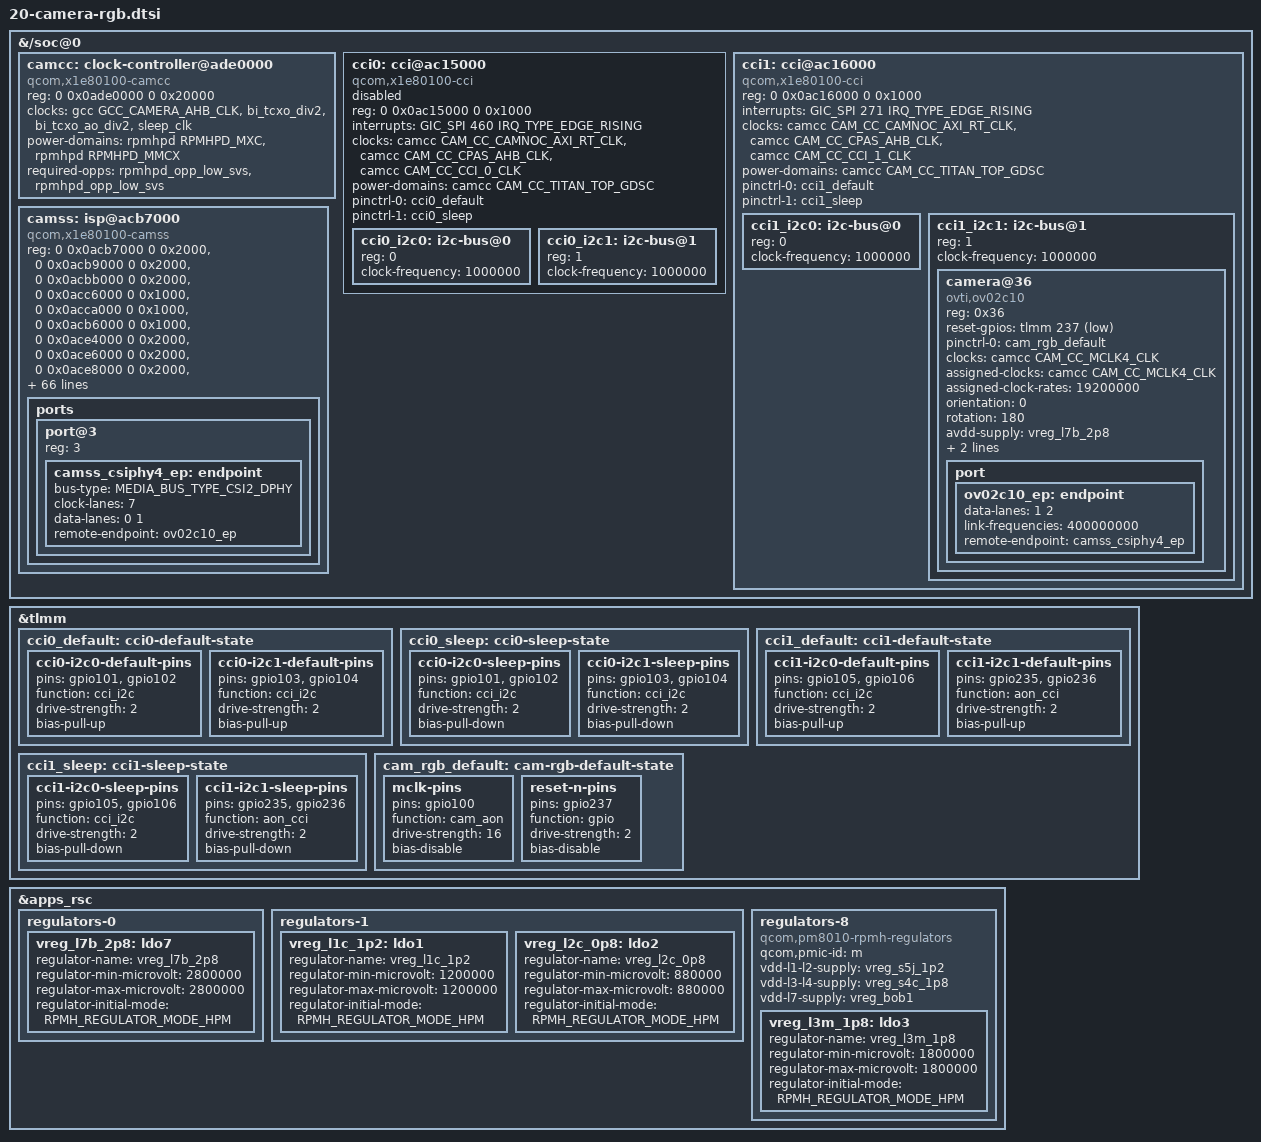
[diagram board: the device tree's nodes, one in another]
// SPDX-License-Identifier: BSD-3-Clause
/*
 * Front RGB camera of the ASUS Vivobook S 15 (S5507QAD), overlay fragment.
 *
 * Part 1 (SoC): camcc, CCI0/CCI1, CAMSS (x1e80100 / hamoa).
 * Part 2 (board): supplies, pins and the OV02C10 sensor.
 *
 * Fedora kernels 7.2 and 7.3 have the drivers (camcc-x1e80100, i2c-qcom-cci,
 * qcom-camss with x1e80100 data), but hamoa.dtsi has none of these nodes,
 * so the overlay adds them completely instead of just enabling them.
 *
 * Origin of the values:
 *  - camcc, cci0, cci1, CCI pins: hamoa.dtsi of the Ubuntu linux-qcom-x1e
 *    7.3.0-21.21 kernel (Bryan O'Donoghue's "x1e80100: Add CAMCC/CCI"
 *    series), identical to HurlyDesousa/linux-aarch64-vivobook patch 0003.
 *  - camss: the "legacy" binding with the CSIPHYs inside CAMSS
 *    (Documentation/devicetree/bindings/media/qcom,x1e80100-camss.yaml of
 *    7.2; no phys/simple-mfd/separate csiphy nodes, that is the newer PHY
 *    API series). Taken from Ubuntu 7.3, which worked on this laptop: the
 *    vfe0/vfe1 register size 0xf000 and the iommus list.
 *  - CSIPHY supplies belong to the board, see part 2.
 *
 * The IR camera fragment (30-camera-ir.dtsi) reuses these nodes: it enables
 * &cci0 and adds its own port@N to &camss.
 */

#include <dt-bindings/clock/qcom,x1e80100-camcc.h>
#include <dt-bindings/clock/qcom,x1e80100-gcc.h>
#include <dt-bindings/gpio/gpio.h>
#include <dt-bindings/interconnect/qcom,icc.h>
#include <dt-bindings/interconnect/qcom,x1e80100-rpmh.h>
#include <dt-bindings/interrupt-controller/arm-gic.h>
#include <dt-bindings/media/video-interfaces.h>
#include <dt-bindings/power/qcom,rpmhpd.h>
#include <dt-bindings/regulator/qcom,rpmh-regulator.h>

/* ======================= SoC part ======================= */

&{/soc@0} {
	camcc: clock-controller@ade0000 {
		compatible = "qcom,x1e80100-camcc";
		reg = <0 0x0ade0000 0 0x20000>;
		clocks = <&gcc GCC_CAMERA_AHB_CLK>,
			 <&bi_tcxo_div2>,
			 <&bi_tcxo_ao_div2>,
			 <&sleep_clk>;
		power-domains = <&rpmhpd RPMHPD_MXC>,
				<&rpmhpd RPMHPD_MMCX>;
		required-opps = <&rpmhpd_opp_low_svs>,
				<&rpmhpd_opp_low_svs>;
		#clock-cells = <1>;
		#reset-cells = <1>;
		#power-domain-cells = <1>;
	};

	cci0: cci@ac15000 {
		compatible = "qcom,x1e80100-cci", "qcom,msm8996-cci";
		reg = <0 0x0ac15000 0 0x1000>;

		interrupts = <GIC_SPI 460 IRQ_TYPE_EDGE_RISING>;

		clocks = <&camcc CAM_CC_CAMNOC_AXI_RT_CLK>,
			 <&camcc CAM_CC_CPAS_AHB_CLK>,
			 <&camcc CAM_CC_CCI_0_CLK>;
		clock-names = "camnoc_axi",
			      "cpas_ahb",
			      "cci";

		power-domains = <&camcc CAM_CC_TITAN_TOP_GDSC>;

		pinctrl-0 = <&cci0_default>;
		pinctrl-1 = <&cci0_sleep>;
		pinctrl-names = "default", "sleep";

		#address-cells = <1>;
		#size-cells = <0>;

		status = "disabled";

		cci0_i2c0: i2c-bus@0 {
			reg = <0>;
			clock-frequency = <1000000>;
			#address-cells = <1>;
			#size-cells = <0>;
		};

		cci0_i2c1: i2c-bus@1 {
			reg = <1>;
			clock-frequency = <1000000>;
			#address-cells = <1>;
			#size-cells = <0>;
		};
	};

	cci1: cci@ac16000 {
		compatible = "qcom,x1e80100-cci", "qcom,msm8996-cci";
		reg = <0 0x0ac16000 0 0x1000>;

		interrupts = <GIC_SPI 271 IRQ_TYPE_EDGE_RISING>;

		clocks = <&camcc CAM_CC_CAMNOC_AXI_RT_CLK>,
			 <&camcc CAM_CC_CPAS_AHB_CLK>,
			 <&camcc CAM_CC_CCI_1_CLK>;
		clock-names = "camnoc_axi",
			      "cpas_ahb",
			      "cci";

		power-domains = <&camcc CAM_CC_TITAN_TOP_GDSC>;

		pinctrl-0 = <&cci1_default>;
		pinctrl-1 = <&cci1_sleep>;
		pinctrl-names = "default", "sleep";

		#address-cells = <1>;
		#size-cells = <0>;

		status = "disabled";

		cci1_i2c0: i2c-bus@0 {
			reg = <0>;
			clock-frequency = <1000000>;
			#address-cells = <1>;
			#size-cells = <0>;
		};

		cci1_i2c1: i2c-bus@1 {
			reg = <1>;
			clock-frequency = <1000000>;
			#address-cells = <1>;
			#size-cells = <0>;
		};
	};

	camss: isp@acb7000 {
		compatible = "qcom,x1e80100-camss";

		reg = <0 0x0acb7000 0 0x2000>,
		      <0 0x0acb9000 0 0x2000>,
		      <0 0x0acbb000 0 0x2000>,
		      <0 0x0acc6000 0 0x1000>,
		      <0 0x0acca000 0 0x1000>,
		      <0 0x0acb6000 0 0x1000>,
		      <0 0x0ace4000 0 0x2000>,
		      <0 0x0ace6000 0 0x2000>,
		      <0 0x0ace8000 0 0x2000>,
		      <0 0x0acec000 0 0x4000>,
		      <0 0x0acf6000 0 0x1000>,
		      <0 0x0acf7000 0 0x1000>,
		      <0 0x0acf8000 0 0x1000>,
		      <0 0x0ac62000 0 0xf000>,
		      <0 0x0ac71000 0 0xf000>,
		      <0 0x0acc7000 0 0x2000>,
		      <0 0x0accb000 0 0x2000>;
		reg-names = "csid0", "csid1", "csid2",
			    "csid_lite0", "csid_lite1",
			    "csid_wrapper",
			    "csiphy0", "csiphy1", "csiphy2", "csiphy4",
			    "csitpg0", "csitpg1", "csitpg2",
			    "vfe0", "vfe1",
			    "vfe_lite0", "vfe_lite1";

		clocks = <&camcc CAM_CC_CAMNOC_AXI_NRT_CLK>,
			 <&camcc CAM_CC_CAMNOC_AXI_RT_CLK>,
			 <&camcc CAM_CC_CORE_AHB_CLK>,
			 <&camcc CAM_CC_CPAS_AHB_CLK>,
			 <&camcc CAM_CC_CPAS_FAST_AHB_CLK>,
			 <&camcc CAM_CC_CPAS_IFE_0_CLK>,
			 <&camcc CAM_CC_CPAS_IFE_1_CLK>,
			 <&camcc CAM_CC_CPAS_IFE_LITE_CLK>,
			 <&camcc CAM_CC_CPHY_RX_CLK_SRC>,
			 <&camcc CAM_CC_CSID_CLK>,
			 <&camcc CAM_CC_CSID_CSIPHY_RX_CLK>,
			 <&camcc CAM_CC_CSIPHY0_CLK>,
			 <&camcc CAM_CC_CSI0PHYTIMER_CLK>,
			 <&camcc CAM_CC_CSIPHY1_CLK>,
			 <&camcc CAM_CC_CSI1PHYTIMER_CLK>,
			 <&camcc CAM_CC_CSIPHY2_CLK>,
			 <&camcc CAM_CC_CSI2PHYTIMER_CLK>,
			 <&camcc CAM_CC_CSIPHY4_CLK>,
			 <&camcc CAM_CC_CSI4PHYTIMER_CLK>,
			 <&gcc GCC_CAMERA_HF_AXI_CLK>,
			 <&gcc GCC_CAMERA_SF_AXI_CLK>,
			 <&camcc CAM_CC_IFE_0_CLK>,
			 <&camcc CAM_CC_IFE_0_FAST_AHB_CLK>,
			 <&camcc CAM_CC_IFE_1_CLK>,
			 <&camcc CAM_CC_IFE_1_FAST_AHB_CLK>,
			 <&camcc CAM_CC_IFE_LITE_CLK>,
			 <&camcc CAM_CC_IFE_LITE_AHB_CLK>,
			 <&camcc CAM_CC_IFE_LITE_CPHY_RX_CLK>,
			 <&camcc CAM_CC_IFE_LITE_CSID_CLK>;
		clock-names = "camnoc_nrt_axi", "camnoc_rt_axi",
			      "core_ahb", "cpas_ahb", "cpas_fast_ahb",
			      "cpas_vfe0", "cpas_vfe1", "cpas_vfe_lite",
			      "cphy_rx_clk_src", "csid", "csid_csiphy_rx",
			      "csiphy0", "csiphy0_timer",
			      "csiphy1", "csiphy1_timer",
			      "csiphy2", "csiphy2_timer",
			      "csiphy4", "csiphy4_timer",
			      "gcc_axi_hf", "gcc_axi_sf",
			      "vfe0", "vfe0_fast_ahb",
			      "vfe1", "vfe1_fast_ahb",
			      "vfe_lite", "vfe_lite_ahb",
			      "vfe_lite_cphy_rx", "vfe_lite_csid";

		interrupts = <GIC_SPI 464 IRQ_TYPE_EDGE_RISING>,
			     <GIC_SPI 466 IRQ_TYPE_EDGE_RISING>,
			     <GIC_SPI 431 IRQ_TYPE_EDGE_RISING>,
			     <GIC_SPI 468 IRQ_TYPE_EDGE_RISING>,
			     <GIC_SPI 359 IRQ_TYPE_EDGE_RISING>,
			     <GIC_SPI 477 IRQ_TYPE_EDGE_RISING>,
			     <GIC_SPI 478 IRQ_TYPE_EDGE_RISING>,
			     <GIC_SPI 479 IRQ_TYPE_EDGE_RISING>,
			     <GIC_SPI 122 IRQ_TYPE_EDGE_RISING>,
			     <GIC_SPI 465 IRQ_TYPE_EDGE_RISING>,
			     <GIC_SPI 467 IRQ_TYPE_EDGE_RISING>,
			     <GIC_SPI 469 IRQ_TYPE_EDGE_RISING>,
			     <GIC_SPI 360 IRQ_TYPE_EDGE_RISING>;
		interrupt-names = "csid0", "csid1", "csid2",
				  "csid_lite0", "csid_lite1",
				  "csiphy0", "csiphy1", "csiphy2", "csiphy4",
				  "vfe0", "vfe1",
				  "vfe_lite0", "vfe_lite1";

		interconnects = <&gem_noc MASTER_APPSS_PROC QCOM_ICC_TAG_ACTIVE_ONLY
				 &config_noc SLAVE_CAMERA_CFG QCOM_ICC_TAG_ACTIVE_ONLY>,
				<&mmss_noc MASTER_CAMNOC_HF QCOM_ICC_TAG_ALWAYS
				 &mc_virt SLAVE_EBI1 QCOM_ICC_TAG_ALWAYS>,
				<&mmss_noc MASTER_CAMNOC_SF QCOM_ICC_TAG_ALWAYS
				 &mc_virt SLAVE_EBI1 QCOM_ICC_TAG_ALWAYS>,
				<&mmss_noc MASTER_CAMNOC_ICP QCOM_ICC_TAG_ALWAYS
				 &mc_virt SLAVE_EBI1 QCOM_ICC_TAG_ALWAYS>;
		interconnect-names = "ahb", "hf_mnoc", "sf_mnoc", "sf_icp_mnoc";

		iommus = <&apps_smmu 0x800 0x60>,
			 <&apps_smmu 0x820 0x60>,
			 <&apps_smmu 0x840 0x60>,
			 <&apps_smmu 0x860 0x60>,
			 <&apps_smmu 0x18a0 0x0>;

		power-domains = <&camcc CAM_CC_IFE_0_GDSC>,
				<&camcc CAM_CC_IFE_1_GDSC>,
				<&camcc CAM_CC_TITAN_TOP_GDSC>;
		power-domain-names = "ife0", "ife1", "top";

		status = "disabled";

		/* port0..3 => csiphy0, csiphy1, csiphy2, csiphy4 (driver: csiphy_id = port number) */
		ports {
			#address-cells = <1>;
			#size-cells = <0>;
		};
	};
};

&tlmm {
	cci0_default: cci0-default-state {
		cci0-i2c0-default-pins {
			pins = "gpio101", "gpio102";
			function = "cci_i2c";
			drive-strength = <2>;
			bias-pull-up;
		};

		cci0-i2c1-default-pins {
			pins = "gpio103", "gpio104";
			function = "cci_i2c";
			drive-strength = <2>;
			bias-pull-up;
		};
	};

	cci0_sleep: cci0-sleep-state {
		cci0-i2c0-sleep-pins {
			pins = "gpio101", "gpio102";
			function = "cci_i2c";
			drive-strength = <2>;
			bias-pull-down;
		};

		cci0-i2c1-sleep-pins {
			pins = "gpio103", "gpio104";
			function = "cci_i2c";
			drive-strength = <2>;
			bias-pull-down;
		};
	};

	cci1_default: cci1-default-state {
		cci1-i2c0-default-pins {
			pins = "gpio105", "gpio106";
			function = "cci_i2c";
			drive-strength = <2>;
			bias-pull-up;
		};

		/* aon_cci: gpio235/236 (AeoB CAMF: TLMMGPIO 0xEB/0xEC, function 1) */
		cci1-i2c1-default-pins {
			pins = "gpio235", "gpio236";
			function = "aon_cci";
			drive-strength = <2>;
			bias-pull-up;
		};
	};

	cci1_sleep: cci1-sleep-state {
		cci1-i2c0-sleep-pins {
			pins = "gpio105", "gpio106";
			function = "cci_i2c";
			drive-strength = <2>;
			bias-pull-down;
		};

		cci1-i2c1-sleep-pins {
			pins = "gpio235", "gpio236";
			function = "aon_cci";
			drive-strength = <2>;
			bias-pull-down;
		};
	};
};

/* ======================= board part: RGB camera ======================= */
/*
 * Front RGB camera OV02C10 on cci1_i2c1 @ 0x36, CSIPHY4 (CAMSS port@3).
 *
 * All sensor values come from the ACPI/AeoB resources of this laptop
 * (alexVinarskis/qcom-aeob-dumps, asus-vivobook-s15-s5507):
 *   CAMF_RES_QRD: PMICVREGVOTE LDO7_B 2.8 V (avdd+dvdd), LDO3_M 1.8 V (dovdd),
 *                 cam_cc_mclk4_clk 19.2 MHz, TLMMGPIO 0xED (237) reset,
 *                 0xEB/0xEC (235/236) aon_cci pins.
 *   SCFG_FRONT_QRD: ov02c10, address 0x6C (8 bit) = 0x36, chip-id 0x5602.
 * The same set gave a picture on Ubuntu 7.3 (bingo1991, 2026-10-05) and a
 * probe with chip-id 0x5602 on Arch 7.2.2 (HurlyDesousa PR #21).
 *
 * Do NOT use l2m/l4m/l7m here: those are the IR camera supplies
 * (CAMI_RES_QRD), see 30-camera-ir.dtsi.
 *
 * CSIPHY supplies: Windows (CAMP_RES_QRD) votes no PMIC rails for the
 * CSIPHY. The rails of the reference design (CRD, Zenbook A14) are used:
 * l2c 0.88 V and l1c 1.2 V, as in bingo1991's working configuration on this
 * laptop. The legacy driver enables them only while streaming.
 */

&apps_rsc {
	/* PM8550 "b": parent vdd-l6-l7-supply = vreg_bob2 is already in the board DTS */
	regulators-0 {
		vreg_l7b_2p8: ldo7 {
			regulator-name = "vreg_l7b_2p8";
			regulator-min-microvolt = <2800000>;
			regulator-max-microvolt = <2800000>;
			regulator-initial-mode = <RPMH_REGULATOR_MODE_HPM>;
		};
	};

	/* PM8550VE "c": parents vdd-l1 = s5j_1p2, vdd-l2 = s1f_0p7 already exist */
	regulators-1 {
		vreg_l1c_1p2: ldo1 {
			regulator-name = "vreg_l1c_1p2";
			regulator-min-microvolt = <1200000>;
			regulator-max-microvolt = <1200000>;
			regulator-initial-mode = <RPMH_REGULATOR_MODE_HPM>;
		};

		vreg_l2c_0p8: ldo2 {
			regulator-name = "vreg_l2c_0p8";
			regulator-min-microvolt = <880000>;
			regulator-max-microvolt = <880000>;
			regulator-initial-mode = <RPMH_REGULATOR_MODE_HPM>;
		};
	};

	/*
	 * PM8010 "m" (camera PMIC), not described in the board DTS. The node
	 * and its supply inputs are declared here; 30-camera-ir.dtsi only adds
	 * its ldo2/ldo4/ldo7, without repeating compatible/supplies.
	 */
	regulators-8 {
		compatible = "qcom,pm8010-rpmh-regulators";
		qcom,pmic-id = "m";

		vdd-l1-l2-supply = <&vreg_s5j_1p2>;
		vdd-l3-l4-supply = <&vreg_s4c_1p8>;
		vdd-l7-supply = <&vreg_bob1>;

		vreg_l3m_1p8: ldo3 {
			regulator-name = "vreg_l3m_1p8";
			regulator-min-microvolt = <1800000>;
			regulator-max-microvolt = <1800000>;
			regulator-initial-mode = <RPMH_REGULATOR_MODE_HPM>;
		};
	};
};

&tlmm {
	cam_rgb_default: cam-rgb-default-state {
		mclk-pins {
			pins = "gpio100";
			function = "cam_aon";
			drive-strength = <16>;
			bias-disable;
		};

		reset-n-pins {
			pins = "gpio237";
			function = "gpio";
			drive-strength = <2>;
			bias-disable;
		};
	};
};

&camss {
	vdd-csiphy-0p8-supply = <&vreg_l2c_0p8>;
	vdd-csiphy-1p2-supply = <&vreg_l1c_1p2>;

	status = "okay";

	ports {
		/* port@3 => CSIPHY4 */
		port@3 {
			reg = <3>;

			camss_csiphy4_ep: endpoint {
				bus-type = <MEDIA_BUS_TYPE_CSI2_DPHY>;
				clock-lanes = <7>;
				data-lanes = <0 1>;
				remote-endpoint = <&ov02c10_ep>;
			};
		};
	};
};

&cci1 {
	status = "okay";
};

&cci1_i2c1 {
	camera@36 {
		compatible = "ovti,ov02c10";
		reg = <0x36>;

		reset-gpios = <&tlmm 237 GPIO_ACTIVE_LOW>;
		pinctrl-names = "default";
		pinctrl-0 = <&cam_rgb_default>;

		clocks = <&camcc CAM_CC_MCLK4_CLK>;
		assigned-clocks = <&camcc CAM_CC_MCLK4_CLK>;
		assigned-clock-rates = <19200000>;

		orientation = <0>;	/* front */
		rotation = <180>;	/* module is mounted upside down (bingo1991) */

		avdd-supply = <&vreg_l7b_2p8>;
		dvdd-supply = <&vreg_l7b_2p8>;
		dovdd-supply = <&vreg_l3m_1p8>;

		port {
			ov02c10_ep: endpoint {
				data-lanes = <1 2>;
				link-frequencies = /bits/ 64 <400000000>;
				remote-endpoint = <&camss_csiphy4_ep>;
			};
		};
	};
};
